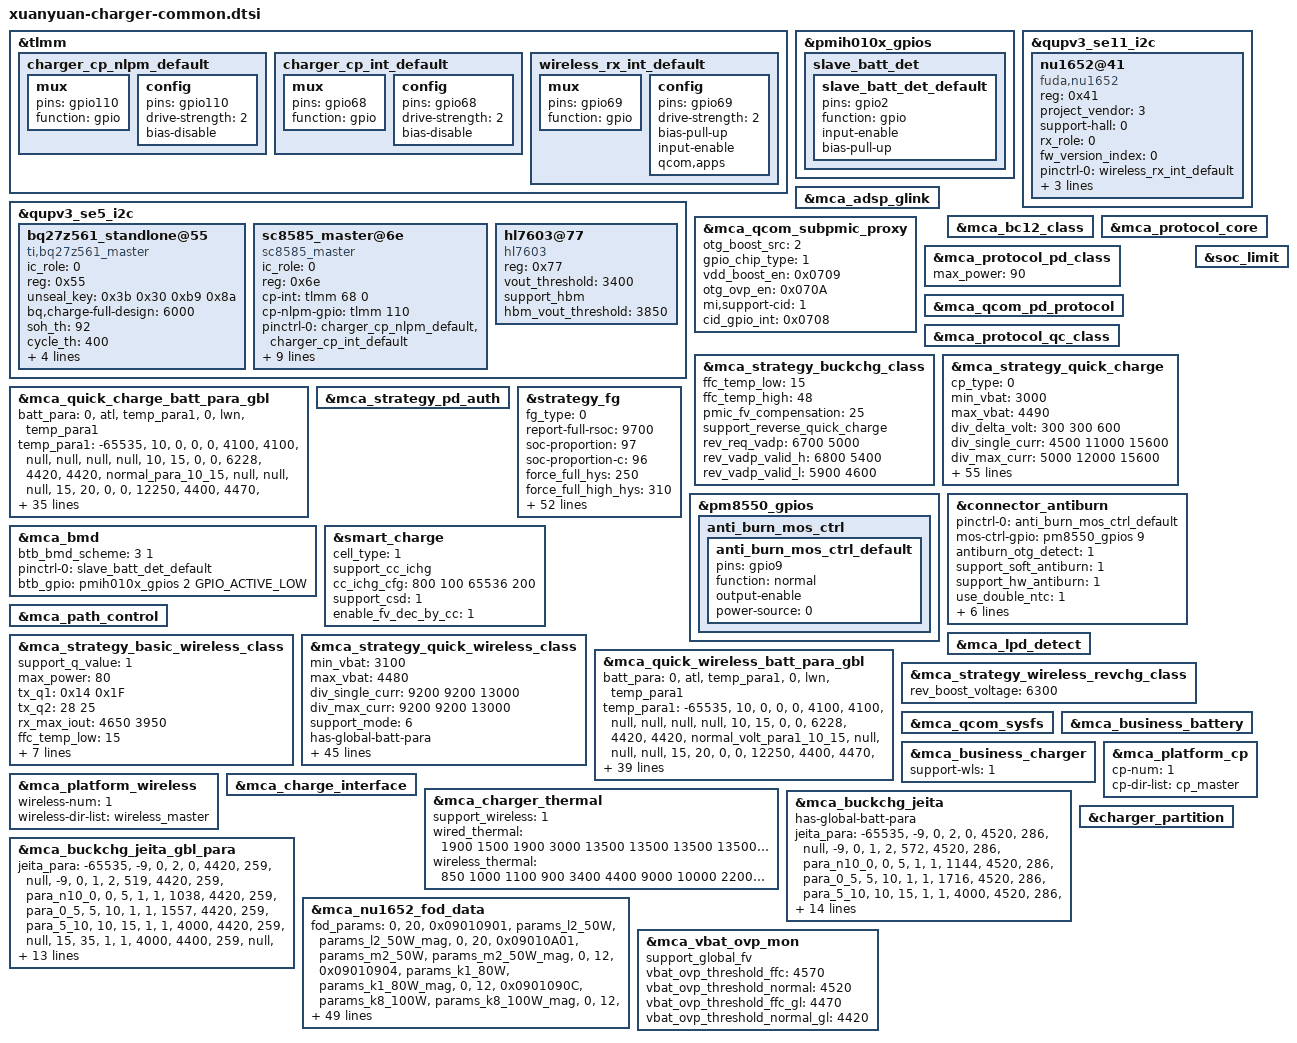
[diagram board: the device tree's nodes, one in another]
#include "mca.dtsi"

&tlmm {
	charger_cp_nlpm_default: charger_cp_nlpm_default {
		mux {
			pins = "gpio110";
			function = "gpio";
		};
		config {
			pins = "gpio110";
			drive-strength = <2>;   /* 2 mA */
			bias-disable;
		};
	};

	charger_cp_int_default: charger_cp_int_default {
		mux {
			pins = "gpio68";
			function = "gpio";
		};
		config {
			pins = "gpio68";
			drive-strength = <2>;   /* 2 mA */
			bias-disable;
		};
	};

	wireless_rx_int_default: wireless_rx_int_default {
		mux {
			pins = "gpio69";
			function = "gpio";
		};

		config {
			pins = "gpio69";
			drive-strength = <2>;
			bias-pull-up;
			input-enable;
			qcom,apps;
		};
	};
};

&pmih010x_gpios {
	slave_batt_det {
		slave_batt_det_default: slave_batt_det_default {
			pins = "gpio2";
			function = "gpio";
			input-enable;
			bias-pull-up;
		};
	};
};


&qupv3_se5_i2c {
	status = "ok";
	#address-cells = <1>;
	#size-cells = <0>;
	bq27z561_standlone@55 {
		compatible = "ti,bq27z561_master";
		ic_role = <0>;
		reg = <0x55>;
		unseal_key = /bits/ 8 <0x3b 0x30 0xb9 0x8a>;
		bq,charge-full-design = <6000>;
		soh_th = <92>;
		cycle_th = <400>;
		cycle_step = <50>;
		resistance-id = <100000>;
		support-version-compatible;
		support_nvt1000_ota = <1>;
		status = "ok";
	};

	sc8585_master@6e {
		compatible = "sc8585_master";
		status = "ok";
		ic_role = <0>;
		reg = <0x6e>;
		cp-int= <&tlmm 68 0>;
		cp-nlpm-gpio = <&tlmm 110 0x00>;
		pinctrl-names = "default";
		pinctrl-0 = <&charger_cp_nlpm_default>, <&charger_cp_int_default>;
		bat-ovp-threshold = <4700>;
		bat-ovp-alarm-threshold = <4650>;
		bus-ovp-threshold = <21000 11000 6000>;
		usb-ovp-threshold = <21000 14000 7500>;
		bus-ocp-threshold = <4650 5500 5000>;
		wpc-ovp-threshold = <21000>;
		out-ovp-threshold = <5000>;
		pmid2-uvp-threshold = <100>;
		pmid2-ovp-threshold = <600>;

	};

	hl7603@77 {
		compatible = "hl7603";
		reg = <0x77>;
		vout_threshold = <3400>;
		support_hbm;
		hbm_vout_threshold = <3850>;
	};
};

&qupv3_se11_i2c {
	status = "ok";
	#address-cells = <1>;
	#size-cells = <0>;
	nu1652@41 {
		compatible = "fuda,nu1652";
		reg = <0x41>;
		project_vendor = <3>;
		support-hall = <0>;
		rx_role = <0>;
		fw_version_index = <0>;
		pinctrl-names = "rx_int_pull_up";
		pinctrl-0 = <&wireless_rx_int_default>;
		rx-int = <&tlmm 69 0x00>;
		pwr-det-int = <&tlmm 96 0x00>;
		sleep-rx-gpio = <&tlmm 94 0x00>;
	};
};

&mca_adsp_glink {
	status = "ok";
};

&mca_bc12_class {
	status = "ok";
};

&mca_qcom_subpmic_proxy {
	status = "ok";
	otg_boost_src = <2>;
	gpio_chip_type = <1>;
	vdd_boost_en = <0x0709>;
	otg_ovp_en = <0x070A>;
	mi,support-cid = <1>;
	cid_gpio_int = <0x0708>;
};

&mca_protocol_core {
	status = "ok";
};

&mca_protocol_pd_class {
	status = "ok";
	max_power = <90>;
};

&mca_qcom_pd_protocol {
	status = "ok";
};

&mca_protocol_qc_class {
	status = "ok";
};

&mca_strategy_buckchg_class {
	status = "ok";
	ffc_temp_low = <15>;
	ffc_temp_high = <48>;
	pmic_fv_compensation = <25>;
	support_reverse_quick_charge;
	rev_req_vadp = <6700 5000>;
	rev_vadp_valid_h = <6800 5400>;
	rev_vadp_valid_l = <5900 4600>;
};

&mca_strategy_quick_charge {
	status = "ok";
	cp_type = <0>;
	min_vbat = <3000>;
	max_vbat = <4490>;
	div_delta_volt = <300 300 600>;
	div_single_curr = <4500 11000 15600>;
	div_max_curr = <5000 12000 15600>;
	max_power = <90000>;
	ibus_compensation = <600 300 200>;
	qc_normal_charge_fv = <4500>;
	pps_taper_vol_hys = <5>;
	pps_taper_fcc_thr = <2100>;
	pps_high_taper_fcc_thr = <2400>;
	hardware_cv = <1>;
	support_mode = <6>;
	has-global-batt-para;
	support_cp_vfc = <1>;
	vfc_iout_fsw_map =
		"12000", "840",
		"10000", "780",
		"6000", "720",
		"3000", "420",
		"0", "300";
	support_curr_monitor = <1>;
	curr_monitor_time_s = <130>;

	vstep_para =
		"1", "2000", "2",
		"2", "2000", "4",
		"4", "8000", "20",
		"4", "4000", "15",
		"4", "1500", "5",
		"4", "1000", "2",
		"4", "600", "2";

	batt_para =
		"0", "atl", "temp_para1",
		"0", "lwn", "temp_para1";
	/* temp_low, temp_high, low_temp_hys, high_temp_hys, max_current, normal_fv, ffc_fv,volt_para_name stage_para_name*/
	temp_para1 =
		"-65535", "10", "0", "0", "0", "4100", "4100", "null", "null", "null", "null",
		"10", "15", "0", "0", "6864",  "4520", "4520", "normal_para_10_15", "null", "null", "null",
		"15", "20", "0", "0", "12250", "4500", "4570", "normal_para_15_20", "ffc_para_15_20", "null", "ffc_stage_15_20",
		"20", "35", "0", "0", "15600", "4500", "4570", "normal_para_20_35", "ffc_para_20_35", "null", "ffc_stage_20_35",
		"35", "40", "0", "0", "15600", "4490", "4570", "normal_para_35_40", "ffc_para_35_40", "null", "ffc_stage_35_40",
		"40", "48", "2", "2", "15600", "4480", "4570", "normal_para_40_48", "ffc_para_40_48", "null", "ffc_stage_40_48",
		"48", "65535", "0", "0", "0", "4100", "4100", "null", "null", "null", "null";

	normal_para_10_15 =
		"4200", "6864", "5720",
		"4513", "5720", "800";

	normal_para_15_20 =
		"4493", "6864", "800";
	ffc_para_15_20 =
		"4250", "12250", "10296",
		"4400", "10296", "8580",
		"4500", "8580", "6864",
		"4563", "6864", "1500";
	ffc_stage_15_20 = <0 1 0 0 0 0 0 0>;

	normal_para_20_35 =
		"4493", "6864", "800";
	ffc_para_20_35 =
		"4300", "15600", "12400",
		"4320", "12400", "10296",
		"4400", "10296", "8580",
		"4500", "8580", "6864",
		"4563", "6864", "1500";
	ffc_stage_20_35 = <0 0 0 0 0 0 0 0 0 0>;

	normal_para_35_40 =
		"4483", "6864", "800";
	ffc_para_35_40 =
		"4300", "15600", "12400",
		"4320", "12400", "10296",
		"4400", "10296", "8580",
		"4500", "8580", "6864",
		"4563", "6864", "2000";
	ffc_stage_35_40 = <0 0 0 0 0 0 0 0 0 0>;

	normal_para_40_48 =
		"4473", "6864", "800";
	ffc_para_40_48 =
		"4300", "15600", "12400",
		"4320", "12400", "10296",
		"4400", "10296", "8580",
		"4500", "8580", "6864",
		"4563", "6864", "2500";
	ffc_stage_40_48 = <0 0 0 0 0 0 0 0 0 0>;
};

&mca_quick_charge_batt_para_gbl {
	batt_para =
		"0", "atl", "temp_para1",
		"0", "lwn", "temp_para1";
	/* temp_low, temp_high, low_temp_hys, high_temp_hys, max_current, normal_fv, ffc_fv,volt_para_name stage_para_name*/
	temp_para1 =
		"-65535", "10", "0", "0", "0", "4100", "4100", "null", "null", "null", "null",
		"10", "15", "0", "0", "6228",  "4420", "4420", "normal_para_10_15", "null", "null", "null",
		"15", "20", "0", "0", "12250", "4400", "4470", "normal_para_15_20", "ffc_para_15_20", "null", "ffc_stage_15_20",
		"20", "35", "0", "0", "15600", "4400", "4470", "normal_para_20_35", "ffc_para_20_35", "null", "ffc_stage_20_35",
		"35", "40", "0", "0", "15600", "4390", "4470", "normal_para_35_40", "ffc_para_35_40", "null", "ffc_stage_35_40",
		"40", "48", "2", "2", "15600", "4380", "4470", "normal_para_40_48", "ffc_para_40_48", "null", "ffc_stage_40_48",
		"48", "65535", "0", "0", "0", "4100", "4100", "null", "null", "null", "null";

	normal_para_10_15 =
		"4200", "6228", "5190",
		"4413", "5190", "800";

	normal_para_15_20 =
		"4250", "12250", "6228",
		"4393", "6228", "800";
	ffc_para_15_20 =
		"4250", "12250", "9342",
		"4380", "9342", "7785",
		"4420", "7785", "6228",
		"4463", "6228", "1500";
	ffc_stage_15_20 = <0 1 0 0 0 0 0 0>;

	normal_para_20_35 =
		"4300", "15600", "6228",
		"4393", "6228", "800";
	ffc_para_20_35 =
		"4300", "15600", "12400",
		"4320", "12400", "9342",
		"4380", "9342", "7785",
		"4420", "7785", "6228",
		"4463", "6228", "1500";
	ffc_stage_20_35 = <0 0 0 0 0 0 0 0 0 0>;

	normal_para_35_40 =
		"4300", "15600", "6228",
		"4383", "6228", "800";
	ffc_para_35_40 =
		"4300", "15600", "12400",
		"4320", "12400", "9342",
		"4380", "9342", "7785",
		"4420", "7785", "6228",
		"4463", "6228", "2000";
	ffc_stage_35_40 = <0 0 0 0 0 0 0 0 0 0>;

	normal_para_40_48 =
		"4300", "15600", "6228",
		"4373", "6228", "800";
	ffc_para_40_48 =
		"4300", "15600", "12400",
		"4320", "12400", "9342",
		"4380", "9342", "7785",
		"4420", "7785", "6228",
		"4463", "6228", "2500";
	ffc_stage_40_48 = <0 0 0 0 0 0 0 0 0 0>;
};

&mca_strategy_pd_auth {
	status = "ok";
};

&strategy_fg {
	status = "ok";
	fg_type = <0>;
	report-full-rsoc = <9700>;
	soc-proportion = <97>;
	soc-proportion-c = <96>;
	force_full_hys = <250>;
	force_full_high_hys = <310>;
	vcutoff_shutdown_delay = <3050>;
	vcutoff_sw = <2900>;
	vcutoff_fw = <3050>;
	support-vpack-low-shutdown;
	support-cc-vcutoff;
	/*temp_low, temp_high, low_temp_hys, high_temp_hys, vterm_para_name*/
	cc_vcutoff_cfg =
		"-65535", "0", "0", "2", "cc_para0",
		"0", "65535", "2", "0", "cc_para1";
	cc_para0 =
		"600", "2900", "2850", "2750",
		"1200", "3150", "3100", "2900",
		"65535", "3250", "3200","2900";
	cc_para1 =
		"600", "3050", "3050", "2900",
		"1200", "3150", "3150", "2900",
		"65535", "3250", "3250", "2900";
	support-dod-vcutoff;
	weight = <24 17 14>;
	/*temp_low, temp_high, low_temp_hys, high_temp_hys, vterm_para_name*/
	dod_vcutoff_cfg =
		"-65535", "-6", "0", "2", "dod_para0",
		"-6", "0", "2", "2", "dod_para1",
		"0", "10", "2", "2", "dod_para2",
		"10", "60", "2", "0", "dod_para3",
		"60", "65535", "2", "0", "dod_para4";

	/*dod_count, vterm_fw, vterm_shutdown_delay, vempty*/
	dod_para0 =
		"84", "2900", "2850", "2750",
		"213", "3000", "2950", "2850",
		"65535", "3050", "3000", "2900";

	dod_para1 =
		"84", "2900", "2850", "2750",
		"213", "3050", "3000", "2900",
		"65535", "3150", "3100", "2900";

	dod_para2 =
		"84", "2950", "2950", "2850",
		"213", "3050", "3050", "2900",
		"65535", "3150", "3150", "2900";


	dod_para3 =
		"84", "3050", "3050", "2900",
		"213", "3150", "3150", "2900",
		"65535", "3250", "3250", "2900";

	dod_para4 =
		"65535", "3430", "3430","2900";

	adapt_power = <90>;
	model-name = "O1_6000mah_90w";
	model-name-global = "O1_5410mah_90w";
	support_full_design_gl;
	charge-full-design = <6000>;
	charge-full-design-gl = <5410>;
	support_dtpt = <1>;
	clear_CC_per_hundred = <0>;
	fg_hightemp_vterm = <4200>;
	support_fl4p0 = <0>;
	support_nvt1000_ota = <1>;
	fl4p0_ffc_safe_iterm = <
		650 750 850 900 1000 1150 1350
		600 700 800 850 950 1050 1250
		500 600 700 750 800 900 1100
		400 500 600 650 700 800 1000
		600 700 800 850 950 1050 1250>;
	support-lossless-rechg = <1>;
	lossless_rechg_cfg = <15 47 300>;
	suppot_RSOC_0_smooth = <1>;
	smooth_temp_unit = <0 150>; //15℃
	smooth_curr_unit = <0 300000 600000 1000000 >;
	smooth_vol_offset = <0x80000000 0 100 200 300 >;
	dischg_smooth_low_temp_unit = <
		10 10 10 10
		20 10 10 10
		40 20 10 10
		80 40 30 20
		150 80 70 50 >;
	dischg_smooth_high_temp_unit = <
		10 10 10 10
		30 20 10 10
		60 40 20 10
		150 70 50 40
		200 150 100 70 >;
	extreme_cold_temp_compemsation =
		"100", "-150", "55",
		"100", "50", "85",
		"100", "150", "80",
		"350", "150", "100",
		"2147483647", "150", "120";
};

&pm8550_gpios {
        anti_burn_mos_ctrl {
                anti_burn_mos_ctrl_default: anti_burn_mos_ctrl_default {
                        pins = "gpio9";
                        function = "normal";
                        output-enable;
                        //drive-strength = <2>;
                        power-source = <0>;
                };
        };
};

&connector_antiburn {
	status = "ok";
	pinctrl-names = "default";
	pinctrl-0 = <&anti_burn_mos_ctrl_default>;
	mos-ctrl-gpio = <&pm8550_gpios 9 0>;
	antiburn_otg_detect = <1>;
	support_soft_antiburn = <1>;
	support_hw_antiburn = <1>;
	use_double_ntc = <1>;
	monitor_interval = <1000>;
	thermal-zone-name = "conn_therm";
	thermal-zone-name2 = "conn_therm2";
	max_temp_increase_rate = <4>; /*ntc temperature increase speed per second.*/
	otg_boost_src = <2>;   //BOOST_SRC_EXTERNAL
	en_src = <0>;      //OTG_EN_BOOST
	//thermal-board-temp-name = "board_sensor_therm";
};

&mca_bmd {
	status = "ok";
	btb_bmd_scheme = <3 1>;
	pinctrl-names = "default";
	pinctrl-0 = <&slave_batt_det_default>;
	btb_gpio = <&pmih010x_gpios 2 GPIO_ACTIVE_LOW>;
};

&smart_charge {
	status = "ok";
	cell_type = <1>;
	support_cc_ichg;
	cc_ichg_cfg = </* cyclecount delta_ichg*/
	800 100
	65536 200>;
	support_csd = <1>;
	enable_fv_dec_by_cc = <1>;
};

&soc_limit {
	status = "ok";
};

&mca_path_control {
	status = "ok";
};

&mca_lpd_detect {
	status = "ok";
};

&mca_strategy_basic_wireless_class {
	status = "ok";
	support_q_value = <1>;
	max_power = <80>;
	//low_inductance_tx_50W, low_inductance_tx_80W
	tx_q1 = /bits/ 8 <0x14 0x1F>;
	tx_q2 = <28 25>;
	rx_max_iout = <4650 3950>;
	ffc_temp_low = <15>;
	ffc_temp_high = <48>;
	soc_limit_fcc = <10000>;
	pmic_fv_compensation = <15>;
	/* standard_tx, musical_box, plate_tx, car_mounted, train_tx, redmi_30w_tx,sailboat_tx ,
		low_inductance_50w_tx, low_inductance_80w_tx, support_fan, magnet_tx*/
	adapter_para_91A1 = "0", "0", "0", "0", "0", "0", "0", "1", "0", "1", "0";
	adapter_para_9135 = "1", "0", "0", "0", "0", "0", "0", "0", "1", "1", "0";
};

&mca_strategy_quick_wireless_class {
	status = "ok";
	min_vbat = <3100>;
	max_vbat = <4480>;
	div_single_curr = <9200 9200 13000>;
	div_max_curr = <9200 9200 13000>;
	support_mode = <6>;
	has-global-batt-para;

	batt_para =
		"0", "atl", "temp_para1",
		"0", "lwn", "temp_para1";
	/* temp_low, temp_high, low_temp_hys, high_temp_hys, max_current, normal_fv, ffc_fv, volt_para_name stage_para_name*/
	temp_para1 =
		"-65535", "10", "0", "0", "0", "4100", "4100", "null", "null", "null", "null",
		"10", "15", "0", "0", "6864", "4520", "4520", "normal_volt_para1_10_15", "null", "null", "null",
		"15", "20", "0", "0", "12250", "4500", "4570", "normal_volt_para1_15_20", "ffc_volt_para1_15_20", "null", "ffc_stage_para1_15_20",
		"20", "35", "2", "2", "15600", "4500", "4570", "normal_volt_para1_20_35", "ffc_volt_para1_20_35", "null", "ffc_stage_para1_20_35",
		"35", "40", "2", "2", "15600", "4490", "4570", "normal_volt_para1_35_40", "ffc_volt_para1_35_40", "null", "ffc_stage_para1_35_40",
		"40", "48", "2", "2", "15600", "4480", "4570", "normal_volt_para1_40_48", "ffc_volt_para1_40_48", "null", "ffc_stage_para1_40_48",
		"48", "65535", "0", "0", "0", "4100", "4100", "null", "null", "null", "null";

	normal_volt_para1_10_15 =
		"4200", "6864", "5720",
		"4510", "5720", "2300";

	normal_volt_para1_15_20 =
		"4490", "6864", "2300";
	ffc_volt_para1_15_20 =
		"4250", "12250", "10296",
		"4400", "10296", "8580",
		"4500", "8580", "6864",
		"4555", "6864", "2300";
	ffc_stage_para1_15_20 = <0 1 0 0 0 0 0 0>;

	normal_volt_para1_20_35 =
		"4490", "6864", "2300";
	ffc_volt_para1_20_35 =
		"4300", "15600", "12400",
		"4350", "12400", "10296",
		"4400", "10296", "8580",
		"4500", "8580", "6864",
		"4555", "6864", "2300";
	ffc_stage_para1_20_35 = <0 1 0 0 0 0 0 0 0 0>;

	normal_volt_para1_35_40 =
		"4480", "6864", "2500";
	ffc_volt_para1_35_40 =
		"4300", "15600", "12400",
		"4350", "12400", "10296",
		"4400", "10296", "8580",
		"4500", "8580", "6864",
		"4555", "6864", "2500";
	ffc_stage_para1_35_40 = <0 1 0 0 0 0 0 0 0 0>;

	normal_volt_para1_40_48 =
		"4470", "6864", "2500";
	ffc_volt_para1_40_48 =
		"4300", "15600", "12400",
		"4350", "12400", "10296",
		"4400", "10296", "8580",
		"4500", "8580", "6864",
		"4530", "6864", "3000";
	ffc_stage_para1_40_48 = <0 1 0 0 0 0 0 0 0 0>;

	vstep_para =
		"1", "2000", "2",
		"2", "3000", "25",
		"2", "2000", "12",
		"2", "1000", "3",
		"2", "500", "2",
		"4", "4000", "25",
		"4", "3000", "25",
		"4", "2000", "12",
		"4", "1000", "3",
		"4", "500", "2",
		"4", "200", "1";
};

&mca_quick_wireless_batt_para_gbl {
	batt_para =
		"0", "atl", "temp_para1",
		"0", "lwn", "temp_para1";
	/* temp_low, temp_high, low_temp_hys, high_temp_hys, max_current, normal_fv, ffc_fv,volt_para_name stage_para_name*/
	temp_para1 =
		"-65535", "10", "0", "0", "0", "4100", "4100", "null", "null", "null", "null",
		"10", "15", "0", "0", "6228",  "4420", "4420", "normal_volt_para1_10_15", "null", "null", "null",
		"15", "20", "0", "0", "12250", "4400", "4470", "normal_volt_para1_15_20", "ffc_volt_para1_15_20", "null", "ffc_stage_para1_15_20",
		"20", "35", "0", "0", "15600", "4400", "4470", "normal_volt_para1_20_35", "ffc_volt_para1_20_35", "null", "ffc_stage_para1_20_35",
		"35", "40", "0", "0", "15600", "4390", "4470", "normal_volt_para1_35_40", "ffc_volt_para1_35_40", "null", "ffc_stage_para1_35_40",
		"40", "48", "2", "2", "15600", "4380", "4470", "normal_volt_para1_40_48", "ffc_volt_para1_40_48", "null", "ffc_stage_para1_40_48",
		"48", "65535", "0", "0", "0", "4100", "4100", "null", "null", "null", "null";

	normal_volt_para1_10_15 =
		"4200", "6228", "5190",
		"4410", "5190", "2300";

	normal_volt_para1_15_20 =
		"4250", "12250", "6228",
		"4390", "6228", "2300";
	ffc_volt_para1_15_20 =
		"4250", "12250", "9342",
		"4380", "9342", "7785",
		"4420", "7785", "6228",
		"4455", "6228", "2300";
	ffc_stage_para1_15_20 = <0 1 0 0 0 0 0 0>;

	normal_volt_para1_20_35 =
		"4300", "15600", "6228",
		"4390", "6228", "2300";
	ffc_volt_para1_20_35 =
		"4300", "15600", "12400",
		"4350", "12400", "9342",
		"4380", "9342", "7785",
		"4420", "7785", "6228",
		"4455", "6228", "2300";
	ffc_stage_para1_20_35 = <0 1 0 0 0 0 0 0 0 0>;

	normal_volt_para1_35_40 =
		"4300", "15600", "6228",
		"4380", "6228", "2500";
	ffc_volt_para1_35_40 =
		"4300", "15600", "12400",
		"4350", "12400", "9342",
		"4380", "9342", "7785",
		"4420", "7785", "6228",
		"4455", "6228", "2500";
	ffc_stage_para1_35_40 = <0 1 0 0 0 0 0 0 0 0>;

	normal_volt_para1_40_48 =
		"4300", "15600", "6228",
		"4370", "6228", "2500";
	ffc_volt_para1_40_48 =
		"4300", "15600", "12400",
		"4350", "12400", "9342",
		"4380", "9342", "7785",
		"4420", "7785", "6228",
		"4430", "6228", "3000";
	ffc_stage_para1_40_48 = <0 1 0 0 0 0 0 0 0 0>;
};

&mca_strategy_wireless_revchg_class{
	status = "ok";
	rev_boost_voltage = <6300>;
};

&mca_qcom_sysfs {
	status = "ok";
};

&mca_business_battery {
	status = "ok";
};

&mca_business_charger {
	support-wls = <1>;
	status = "ok";
};

&mca_platform_cp {
	status = "ok";
	cp-num = <1>;
	cp-dir-list = "cp_master";
};

&mca_platform_wireless {
	status = "ok";
	wireless-num = <1>;
	wireless-dir-list = "wireless_master";
};

&mca_charge_interface
{
	status = "ok";
};

&mca_charger_thermal
{
	status = "ok";
	support_wireless = <1>;
	/* 5v_in 9v_in 5v_ichg 9v_ichg div1_single div1_multi div2_single div2_multi div4_single div4_multi*/
	wired_thermal = <
	1900 1500 1900 3000 13500 13500 13500 13500 13500 13500 /* level 1 */
	1900 1500 1900 3000 11000 11000 11000 11000 11000 11000 /* level 2 */
	1900 1500 1900 3000 9000  9000  9000  9000  9000  9000  /* level 3 */
	1900 1450 1900 3000 8000  8000  8000  8000  8000  8000  /* level 4 */
	1900 1400 1900 3000 7000  7000  7000  7000  7000  7000  /* level 5 */
	1900 1350 1900 2800 6000  6000  6000  6000  6000  6000  /* level 6 */
	1900 1300 1900 2600 5000  5000  5000  5000  5000  5000  /* level 7 */
	1900 1150 1900 2310 4000  4000  4000  4000  4000  4000  /* level 8 */
	1700 1100 1700 2200 3500  3500  3500  3500  3500  3500  /* level 9 */
	1600 1000 1600 2000 3000  3000  3000  3000  3000  3000  /* level 10 */
	1400 900  1500 2000 2500  2500  2500  2500  2500  2500  /* level 11 */
	1200 850  1500 2000 2000  2000  2000  2000  2000  2000  /* level 12 */
	1100 750  1500 1500 1500  1500  1500  1500  1500  1500  /* level 13 */
	1100 650  1000 1000 1000  1000  1000  1000  1000  1000  /* level 14 */
	1100 600  500  500  500   500   500   500   500   500   /* level 15 */
	>;
	/* bpp_in bpp_qc2 bpp_qc3 epp_in cp_20w cp_30w cp_50w cp_80w voice_box magnet_30w*/
	wireless_thermal = <
	850 1000 1100 900 3400 4400 9000 10000 2200 4400 /* level 1 */
	850 1000 1100 750 3200 4200 8000  9000 2200 4200 /* level 2 */
	850 1000 1100 650 2200 3400 7000  8100 1000 3400 /* level 3 */
	700 1000 1100 650 1800 2800 6000  7200 1000 2800 /* level 4 */
	700 1000  700 650 1500 2600 5000  6300  800 2600 /* level 5 */
	500 1000  700 650 1300 2200 4000  5000  800 2200 /* level 6 */
	500  700  600 400 1100 2200 3500  4500  700 2200 /* level 7 */
	500  700  600 400 1000 1800 3000  4000  700 1800 /* level 8 */
	500  500  500 300  800 1100 2500  3200  600 1100 /* level 9 */
	400  500  500 300  700 1000 2000  2500  600 1000 /* level 10 */
	400  500  500 250  600  800 1500  1500  500  800 /* level 11 */
	400  500  500 250  500  700 1000  1000  500  700 /* level 12 */
	300  500  500 250  500  600  800   800  400  600  /* level 13 */
	300  400  400 200  400  500  500   500  400  500  /* level 14 */
	300  300  300 150  300  400  400   400  300  400  /* level 15 */
	>;
};

&mca_buckchg_jeita
{
	status = "ok";
	has-global-batt-para;
	/* temp_low, temp_high, low_temp_hys, high_temp_hys, max_current, vterm, iterm volt_para_name */
	jeita_para =
		"-65535", "-9", "0", "2", "0", "4520", "286", "null",
		"-9", "0", "1", "2", "572", "4520", "286", "para_n10_0",
		"0", "5", "1", "1", "1144", "4520", "286", "para_0_5",
		"5", "10", "1", "1", "1716", "4520", "286", "para_5_10",
		"10", "15", "1", "1", "4000", "4520", "286", "null",
		"15", "35", "1", "1", "4000", "4500", "286", "null",
		"35", "40", "1", "1", "4000", "4490", "286", "null",
		"40", "48", "1", "0", "4000", "4480", "286", "null",
		"48", "55", "2", "2", "2860", "4060", "286", "null",
		"55", "65535", "2", "2", "0", "4060", "286", "null";

	para_n10_0 =
		"4200", "572",
		"4520", "457";
	para_0_5 =
		"4200", "1144",
		"4520", "858";
	para_5_10 =
		"4200", "1716",
		"4520", "1144";

	jeita_para_ffc =
		"15", "20", "2", "1", "4000", "4570", "915", "null",
		"20", "35", "1", "2", "4000", "4570", "1144", "null",
		"35", "40", "2", "1", "4000", "4570", "1659", "null",
		"40", "48", "1", "0", "4000", "4570", "2231", "null",
		"48", "55", "2", "2", "2890", "4060", "289", "null",
		"55", "65535", "2", "2", "0", "4060", "289", "null";
};

&mca_buckchg_jeita_gbl_para {
	/* temp_low, temp_high, low_temp_hys, high_temp_hys, max_current, vterm, iterm volt_para_name */
	jeita_para =
		"-65535", "-9", "0", "2", "0", "4420", "259", "null",
		"-9", "0", "1", "2", "519", "4420", "259", "para_n10_0",
		"0", "5", "1", "1", "1038", "4420", "259", "para_0_5",
		"5", "10", "1", "1", "1557", "4420", "259", "para_5_10",
		"10", "15", "1", "1", "4000", "4420", "259", "null",
		"15", "35", "1", "1", "4000", "4400", "259", "null",
		"35", "40", "1", "1", "4000", "4390", "259", "null",
		"40", "48", "1", "0", "4000", "4380", "259", "null",
		"48", "55", "2", "2", "2595", "4060", "259", "null",
		"55", "65535", "2", "2", "0", "4060", "259", "null";

	para_n10_0 =
		"4200", "519",
		"4420", "415";
	para_0_5 =
		"4200", "1038",
		"4420", "778";
	para_5_10 =
		"4200", "1557",
		"4420", "1038";

	jeita_para_ffc =
		"15", "20", "2", "1", "4000", "4470", "822", "null",
		"20", "35", "1", "2", "4000", "4470", "1028", "null",
		"35", "40", "2", "1", "4000", "4470", "1439", "null",
		"40", "48", "1", "0", "4000", "4470", "1953", "null",
		"48", "55", "2", "2", "2595", "4060", "257", "null",
		"55", "65535", "2", "2", "0", "4060", "257", "null";
};

&mca_nu1652_fod_data
{
	fod_params =
		"0", "20", "0x09010901", "params_l2_50W", "params_l2_50W_mag",
		"0", "20", "0x09010A01", "params_m2_50W", "params_m2_50W_mag",
		"0", "12", "0x09010904", "params_k1_80W", "params_k1_80W_mag",
		"0", "12", "0x0901090C", "params_k8_100W", "params_k8_100W_mag",
		"0", "12", "0x0901010B", "params_j1s_55W", "params_j1s_55W_mag",
		"0", "20", "0x09010407", "params_white_stand_30W", "params_white_stand_30W_mag",
		"0", "12", "0x09080607", "params_bluetooth_30W", "params_bluetooth_30W",
		"0", "12", "0x09010506", "params_moving_20W", "params_moving_20W_mag",
		"0", "12", "0x09080108", "params_zimi_20W", "params_zimi_20W_mag",
		"0", "12", "0x06010101", "params_white_20W", "params_white_20W",
		"0", "12", "0x07030801", "params_power_bank_30W", "params_power_bank_30W",
		"0", "12", "0x06020801", "params_zimi_car_20W", "params_zimi_car_20W_mag",
		"0", "12", "0x0C090906", "params_multcoil_20W", "params_multcoil_20W_mag",
		"0", "12", "0x0C090908", "params_multcoil_20W", "params_multcoil_20W_mag",
		"0", "12", "0x09010907", "params_redmi_disc_30W", "params_redmi_disc_30W_mag",
		"0", "20", "0x09010305", "params_n1_80W", "params_n1_80W",			/* adapter type > 12 */
		"0", "20", "0x09010305", "params_n1_80W_10V", "params_n1_80W_10V",	/* adapter type <= 12 */
		"0", "12", "0x09010A07", "params_double_coil_30W", "params_double_coil_30W_mag",
		"0", "12", "0x09018B07", "params_magnet_30W", "params_magnet_30W_mag";

	fod_params_default =
		"0", "20", "0x00000000", "params_default", "params_default";
	params_default = /bits/ 8 <
		10 28
		8  24
		7  22
		7  20
		6  20
		5  20
		5  20
		5  20
		5  20
		5  20
		4  20
		4  20
		4  20
		4  20
		4  20
		4  20
		4  20
		4  20
		4  20
		4  20
	>;

	params_l2_50W = /bits/ 8 <
		2 15
		2 15
		2 15
		1  8
		1  8
		1  8
		1  8
		1  8
		1  5
		1  5
		1  5
		1  5
		1  5
		1  5
		1  9
		1  9
		1  8
		1  5
		1  5
		1  5
	>;

	params_l2_50W_mag = /bits/ 8 <
		2 15
		2 15
		2 15
		1  8
		1  8
		1  8
		1  8
		1  8
		1  5
		1  5
		1  5
		1  5
		1  5
		1  5
		1  9
		1  9
		1  8
		1  5
		1  5
		1  5
	>;

	params_m2_50W = /bits/ 8 <
		25 40
		25 40
		25 40
		16 25
		15 20
		10 15
		0  10
		0  10
		1  10
		1  10
		1  10
		1  10
		1  10
		1  10
		1  10
		1  10
		1  10
		1  10
		1  10
		1  10
	>;

	params_m2_50W_mag = /bits/ 8 <
		25 40
		25 30
		25 30
		0  20
		0  10
		0  12
		0  10
		0  10
		1  10
		1  10
		1  10
		1  10
		1  10
		1  10
		1  10
		1  10
		1  10
		1  10
		1  10
		1  10
	>;

	params_n1_80W = /bits/ 8 <
		0  25
		0  20
		5  10
		5  10
		4  25
		2  25
		4  15
		5  10
		6  10
		6  20
		6  20
		7  0
		7  0
		7  0
		7  0
		7  0
		7  0
		7  0
		7  0
		7  0
	>;

	params_n1_80W_10V = /bits/ 8 <
		0  20
		0  0
		0  0
		0  5
		0  10
		0  6
		0  7
		0  7
		1  7
		1  10
		1  10
		1  10
		1  10
		1  10
		1  10
		1  10
		1  10
		1  10
		1  10
		1  10
	>;

	params_white_stand_30W = /bits/ 8 <
		2  15
		2  15
		2  15
		1  8
		1  8
		1  8
		1  8
		1  8
		1  5
		1  5
		1  5
		1  5
		1  5
		1  5
		1  9
		1  9
		1  8
		1  5
		1  5
		1  5
	>;

	params_white_stand_30W_mag = /bits/ 8 <
		2  15
		2  15
		2  15
		1  8
		1  8
		1  8
		1  8
		1  8
		1  5
		1  5
		1  5
		1  5
		1  5
		1  5
		1  9
		1  9
		1  8
		1  5
		1  5
		1  5
	>;

	params_zimi_car_20W = /bits/ 8 <
		0  20
		0  20
		0  20
		0  20
		0  20
		0  20
		5  20
		5  20
		3  20
		3  20
		3  20
		3  20
		3  20
		3  20
		3  20
		3  20
		3  20
		3  20
		3  20
		3  20
	>;
};

&charger_partition
{
	status = "ok";
};

&mca_vbat_ovp_mon {
	support_global_fv;
	vbat_ovp_threshold_ffc = <4570>;
	vbat_ovp_threshold_normal = <4520>;
	vbat_ovp_threshold_ffc_gl = <4470>;
	vbat_ovp_threshold_normal_gl = <4420>;
	status = "ok";
};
